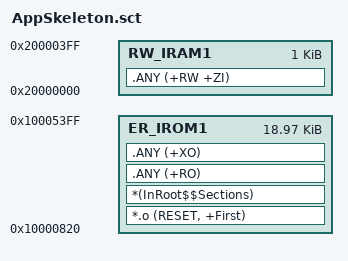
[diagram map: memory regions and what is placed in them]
; *************************************************************
; *** Scatter-Loading Description File generated by uVision ***
; *************************************************************

LR_IROM1 0x10000820 0x00004BE0  {    ; load region size_region
  ER_IROM1 0x10000820 0x00004BE0  {  ; load address = execution address
   *.o (RESET, +First)
   *(InRoot$$Sections)
   .ANY (+RO)
   .ANY (+XO)
  }
  RW_IRAM1 0x20000000 0x00000400  {  ; RW data
   .ANY (+RW +ZI)
  }
}

